# ADuCM350 register map
Vendor: Analog Devices; Series: ARMCM3; File version: 0.1
CPU: CM3 r2p1, little endian, no MPU, no FPU, 3 interrupt priority bits
Registers are 16-bit, access not given, no defined reset value unless marked. A register's access mark holds for its fields unless they carry their own. Offsets are from the block's base; [hi:lo] are bit positions; {n}, {i} and the like mark numbered series.

## GPT2 — General Purpose Timer2
Base 0x40000800
0x00 REG_GPT2_GPTLD — 16-bit load value
  [15:0] VALUE — Load value
0x04 REG_GPT2_GPTVAL — 16-bit timer value
  [15:0] VALUE — Current value
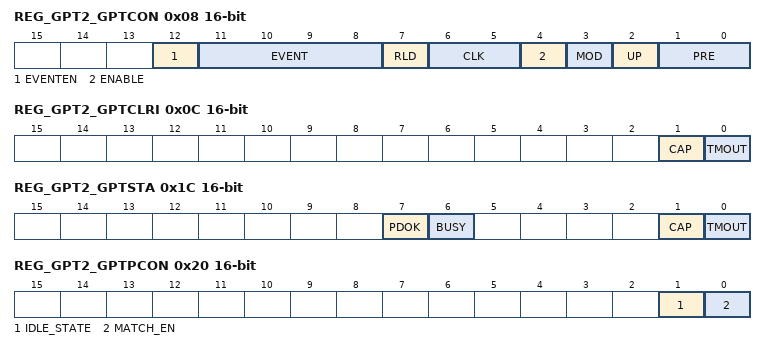
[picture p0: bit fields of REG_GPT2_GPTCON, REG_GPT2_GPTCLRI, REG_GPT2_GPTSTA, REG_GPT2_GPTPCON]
0x08 REG_GPT2_GPTCON — Control Register
  [12] EVENTEN — Enable time capture of an event
    0=DIS; 1=EN
  [11:8] EVENT — Event Select, selects 1 of the available events.
    0=WUT (- Wakeup Timer); {v}=EXT{v-1} (- External interrupt {v-1}) (v=1..8); 9=T3 (- Watchdog timer); 10=T1 (- Timer1); 11=ADC0; 12=ADC1; 13=STEP; 14=DMADONE; 15=FEE (- Flash controller)
  [7] RLD — Timer reload on write to clear register
    0=DIS; 1=EN
  [6:5] CLK — Clock Select
    0=UCLK (- System Clock); 1=PCLK (- Peripheral clock); 2=LFOSC (- Internal 32 kHz Oscillator); 3=LFXTAL (- External 32 kHz crystal)
  [4] ENABLE
    0=DIS; 1=EN
  [3] MOD — Mode
    0=FREERUN; 1=PERIODIC
  [2] UP — Count-up
    0=DIS; 1=EN
  [1:0] PRE — Prescaler
    0=DIV1; 1=DIV16; 2=DIV256; 3=DIV32768 (- If the selected clock source is UCLK then this setting results in a prescaler of 4.)
0x0C REG_GPT2_GPTCLRI — Clear Interrupt register
  [1] CAP — Clear captured event interrupt
    1=CLR
  [0] TMOUT — Clear timeout interrupt
    1=CLR
0x10 REG_GPT2_GPTCAP — Capture
  [15:0] VALUE — Capture value
0x14 REG_GPT2_GPTALD — 16-bit load value, asynchronous
  [15:0] ALOAD — Load value
0x18 REG_GPT2_GPTAVAL — 16-bit timer value, asynchronous
  [15:0] AVALUE — Value
0x1C REG_GPT2_GPTSTA — Status
  [7] PDOK — GPTI Sync
  [6] BUSY — Timer Busy
  [1] CAP — Capture event pending
  [0] TMOUT — Timer timeout
0x20 REG_GPT2_GPTPCON — PWM Control Register
  [1] IDLE_STATE — Idle Hi/Lo
  [0] MATCH_EN — High or Toggle
0x24 REG_GPT2_GPTPMAT — PWM Match Value
  [15:0] MATCH_VAL — PWM Match value

## PWR — Power Management Unit
Base 0x40002400
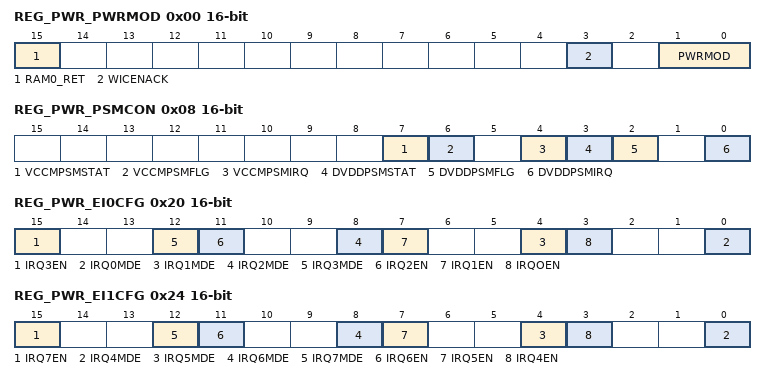
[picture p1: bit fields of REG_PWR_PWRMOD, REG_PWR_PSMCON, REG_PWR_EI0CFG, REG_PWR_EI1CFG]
0x00 REG_PWR_PWRMOD — PWR Power modes
  [15] RAM0_RET — Retention for RAM 0
  [3] WICENACK — For Deepsleep mode only
    0=DIS; 1=EN
  [1:0] PWRMOD — Power modes control bits
    0=FULLACTIVE; 1=CORESLEEP; 2=SYSSLEEP; 3=HIBERNATE
0x04 REG_PWR_PWRKEY — PWR Key protection for PWRMOD
  [15:0] VALUE — Key value
    0x4859=KEY1; 0xF27B=KEY2
0x08 REG_PWR_PSMCON — PWR PSM Configuration
  [7] VCCMPSMSTAT — VCCM PSM current status
  [6] VCCMPSMFLG — VCCM PSM sticky flag
  [4] VCCMPSMIRQ — disable VCCM PSM to generate NMI interrupt
  [3] DVDDPSMSTAT — DVDD PSM current status
  [2] DVDDPSMFLG — DVDD PSM sticky flag.
  [0] DVDDPSMIRQ — disable DVDD PSM to generate NMI interrupt
0x0C REG_PWR_OSCKEY — PWR Key protection for OSCCTRL
  [15:0] VALUE — Key value
    0xCB14=KEY
0x10 REG_PWR_OSCCTRL — PWR Oscillator control
  [15:0] VALUE
0x20 REG_PWR_EI0CFG — PWR External Interrupt configuration 0
  [15] IRQ3EN — External Interrupt 3 enable bit
  [4n] IRQ{n}MDE (n=0..3) — External Interrupt {n} Mode registers
  [11] IRQ2EN — External Interrupt 2 Enable bit
  [7] IRQ1EN — External Interrupt 1 Enable bit
  [3] IRQOEN — External Interrupt 0 Enable bit
0x24 REG_PWR_EI1CFG — PWR External Interrupt configuration 1
  [15] IRQ7EN — External Interrupt 7 enable bit
  [4n-16] IRQ{n}MDE (n=4..7) — External Interrupt {n} Mode registers
  [11] IRQ6EN — External Interrupt 6 Enable bit
  [7] IRQ5EN — External Interrupt 5 Enable bit
  [3] IRQ4EN — External Interrupt 4 Enable bit
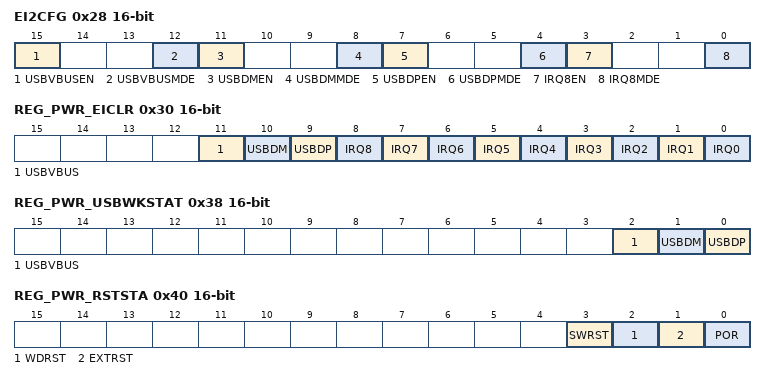
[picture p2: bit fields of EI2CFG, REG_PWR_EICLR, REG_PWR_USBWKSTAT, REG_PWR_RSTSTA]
0x28 EI2CFG — PWR External Interrupt configuration 2
  [15] USBVBUSEN — USB VBUS Detection Enable bit
  [12] USBVBUSMDE — USB VBUS Detection Mode registers
  [11] USBDMEN — USB DM Detection Enable bit
  [8] USBDMMDE — USB DM Detection Mode registers
  [7] USBDPEN — USB DP Detection Enable bit
  [4] USBDPMDE — USB DP Detection Mode registers
  [3] IRQ8EN — External Interrupt 8 Enable bit
  [0] IRQ8MDE — External Interrupt 8 Mode registers
0x30 REG_PWR_EICLR — PWR External Interrupt clear
  [11] USBVBUS — USB VBUS detection
  [10] USBDM — USB DM detection
  [9] USBDP — USB DP detection
  [n] IRQ{n} (n=0..8) — External interrupt {n}
0x34 REG_PWR_NMICLR — PWR Non-maskable interrupt clear
  [0] CLEAR — NMI clear
0x38 REG_PWR_USBWKSTAT — PWR USB Wakeup Status
  [2] USBVBUS — USB VBUS event status
  [1] USBDM — USB DM event status
  [0] USBDP — USB DP event status
0x40 REG_PWR_RSTSTA — PWR Reset status
  [3] SWRST — Software reset
  [2] WDRST — Watchdog timeout
  [1] EXTRST — External reset
  [0] POR — Power-on reset
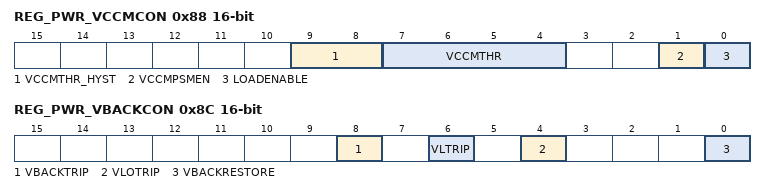
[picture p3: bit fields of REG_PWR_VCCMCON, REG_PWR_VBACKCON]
0x88 REG_PWR_VCCMCON — PWR VCCM Control and Status
  [9:8] VCCMTHR_HYST — VCCM Threshold hysteresis
  [7:4] VCCMTHR — VCCM Threshold adjust
  [1] VCCMPSMEN — VCCM power supply monitoring enable
  [0] LOADENABLE — Enabling 820 ohm load
0x8C REG_PWR_VBACKCON — PWR VBACK control and status
  [8] VBACKTRIP — Vback trip point adjust
  [6] VLTRIP — Vlo trip hysteresis
  [4] VLOTRIP — Vlo trip level
  [0] VBACKRESTORE — VBACK Restore level
